# psoc6_01 register map
Vendor: Cypress Semiconductor; Series: PSoC6_01; File version: 1.0
CPU: CM4 r0p1, little endian, MPU, FPU, VTOR, 3 interrupt priority bits
Registers are 32-bit, read-write, reset 0x0 unless marked. A register's access mark holds for its fields unless they carry their own. Offsets are from the block's base; [hi:lo] are bit positions; {n}, {i} and the like mark numbered series.

## SCB0 (part 1 of 2) — Serial Communications Block (SPI/UART/I2C)
Base 0x40610000
Same registers: SCB{n} {0x40610000+0x10000*n} (n=1..8)
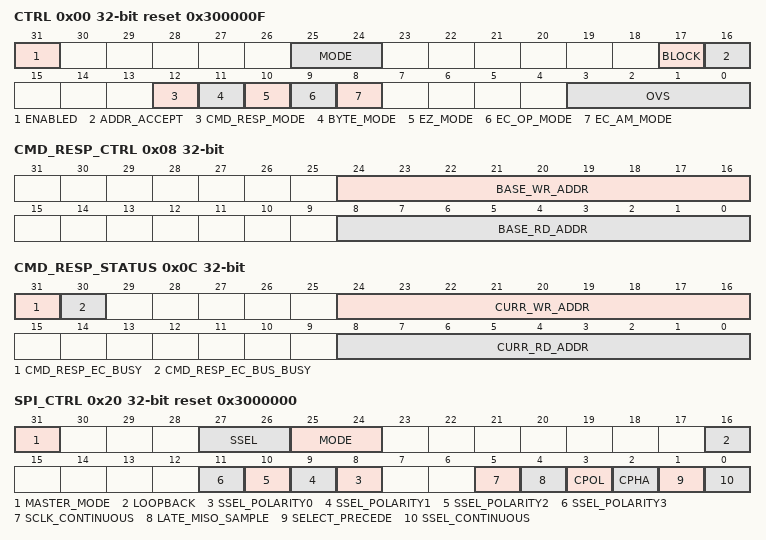
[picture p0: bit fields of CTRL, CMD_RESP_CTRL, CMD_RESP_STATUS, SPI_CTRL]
0x00 CTRL reset 0x300000F — Generic control
  [31] ENABLED — 0': Block Disabled '1': Block Enabled The proper order in which to initialize the SCB is as follows: - Program protocol specific information using SPI_CTRL, UART_CTRL (and UART_TX_CTRL and UART_RX_CTRL) or I2C_CTRL. This includes selection of a submode, master/slave functionality and transmitter/receiver functionality when applicable. - Program generic transmitter (TX_CTRL) and receiver (RX_CTRL) information. This includes enabling of the transmitter and receiver functionality. - Program transmitter FIFO (TX_FIFO_CTRL) and receiver FIFO (RX_FIFO_CTRL) information. - Program CTRL to enable SCB, select the specific operation mode and oversampling factor. When the SCB is enabled, no control information should be changed. Changes must be made AFTER disabling the SCB, e.g. to modify the operation mode (from I2C to SPI) or to go from externally to internally clocked. The change takes effect after the SCB is re-enabled. Note that disabling the SCB will cause re-initialization of the design and associated state is lost (e.g. FIFO content).
  [25:24] MODE
    0=I2C (N/A); 1=SPI (N/A); 2=UART (N/A)
  [17] BLOCK — Only used in externally clocked mode. If the externally clocked logic and the CPU access the EZ memory at the same time this bit determines whether a CPU access should block and result in bus wait states '0': Do not block, but ingore a write and return 0xffff:ffff for a read '1': Block, resulting in CPU wait states. If BLOCK is '0' and the accesses collide, CPU read operations return 0xffff:ffff and CPU write operations are ignored. Colliding accesses are registered as interrupt causes: field BLOCKED of the INTR_TX and INTR_RX registers.
  [16] ADDR_ACCEPT — Determines whether a received matching address is accepted in the RX FIFO:. '0': Matching address does not go in RX FIFO '1': Match address does go in RX FIFO In I2C mode, this field is used to allow the slave to put the received slave address or general call address in the RX FIFO. Note that a received matching address is put in the RX FIFO when this bit is '1' for both I2C read and write transfers. In multi-processor UART receiver mode, this field is used to allow the receiver to put the received address in the RX FIFO. Note: non-matching addresses are never put in the RX FIFO. In SPI mode this field must be '0'
  [12] CMD_RESP_MODE — Determines CMD_RESP mode of operation: '0': CMD_RESP mode disabled. '1': CMD_RESP mode enabled (also requires EC_AM_MODE and EC_OP_MODE to be set to '1'). In CMD_RESP mode, a meta protocol is applied to the serial interface protocol. This meta protocol adds meaning to the data frames transferred by the serial interface protocol: a data frame can represent a write memory data element or a read memory data element. The difference from EZ mode is that the address is written by the CPU, not the interface master. CMD_RESP mode can only be used for synchronous serial interface protocols (SPI and I2C) in slave mode. In SPI mode, only Motorola submode (all Motorola modes: 0, 1, 2, 3) is supported. The external master should use continuous data frames; i.e. data frames not seperated by slave deselection. In CMD_RESP mode, data frames should 8-bit in size and should be transmitted and received with the Most Significant Bit (MSB) first. In UART mode this field must be '0'.
  [11] BYTE_MODE
  [10] EZ_MODE — This field determines if EZ mode is enabled or disabled for the SCB block '0': EZ Mode Disabled '1': EZ Mode Enabled In EZ mode, a meta protocol is applied to the serial interface protocol. This meta protocol adds meaning to the data frames transferred by the serial interface protocol: a data frame can represent a memory address, a write memory data element or a read memory data element. EZ mode can only be used for synchronous serial interface protocols (SPI and I2C) in slave mode. In SPI mode, only Motorola submode (all Motorola modes: 0, 1, 2, 3) is supported. The external master should use continuous data frames; i.e. data frames not seperated by slave deselection. In EZ mode, data frames should 8-bit in size and should be transmitted and received with the Most Significant Bit (MSB) first. In UART mode this field must be '0'.
  [9] EC_OP_MODE — This field specifies the clocking for the SCB block after the address phase '0': Internally clocked mode '1': externally clocked mode In internally clocked mode, the serial interface protocols run off the clk_scb. In externally clocked mode, the serial interface protocols run off the clock as provided by the serial interface. Externally clocked operation mode is only used for synchronous serial interface protocols (SPI and I2C) in slave mode. In SPI mode, only Motorola submode (all Motorola modes: 0, 1, 2, 3) is supported. In UART mode this field must be '0'.
  [8] EC_AM_MODE — This field specifies the clocking for the address matching (I2C slave) or slave selection detection logic (SPI slave) '0': Internally clocked mode '1': Externally clocked mode In internally clocked mode the address detection(and slave selection detection) is done by clk_scb, and thus won't be done in deep sleep power mode as clk_scb isn't active. In externally clocked mode the address detection is done by the I2C/SPI interface clock. This allows for the device to be awoken on I2C salve address match and SPI slave select assertion. The clocking for the rest of the logic is determined by CTRL.EC_OP_MODE. Externally clocked mode is only used for synchronous serial interface protocols (SPI and I2C) in slave mode. In SPI mode, only Motorola submode (all Motorola modes: 0, 1, 2, 3) is supported. In UART mode this field must be '0'.
  [3:0] OVS
0x04 STATUS ro reset not defined — Generic status
  [0] EC_BUSY — Inidicates whether the externally clocked logic is potentially accessing the EZ memory (this is only possible in EZ and CMD_RESP mode). This bit can be used by SW to determine whether it is safe for the CPU to access the EZ memory (without bus wait states (a blocked CPU access) or bus errors being generated). Note that the INTR_TX.BLOCKED and INTR_RX.BLOCKED interrupt causes are used to indicate whether CPU access was actually blocked by externally clocked logic.
0x08 CMD_RESP_CTRL — Command/response control
  [24:16] BASE_WR_ADDR — I2C/SPI write base address for CMD_RESP mode. At the start of a write transfer this BASE_WR_ADDR is copied to CMD_RESP_STATUS.CURR_WR_ADDR. This field should not be modified during ongoing bus transfers.
  [8:0] BASE_RD_ADDR — I2C/SPI read base address for CMD_RESP mode. At the start of a read transfer this BASE_RD_ADDR is copied to CMD_RESP_STATUS.CURR_RD_ADDR. This field should not be modified during ongoing bus transfers.
0x0C CMD_RESP_STATUS ro reset not defined — Command/response status
  [31] CMD_RESP_EC_BUSY
  [30] CMD_RESP_EC_BUS_BUSY — Indicates whether there is an ongoing bus transfer to the SCB. '0': no ongoing bus transfer. '1': ongoing bus transfer. For SPI, the field is '1' when slave mode is selected. For I2C, the field is set to '1' at a I2C START/RESTART. In case of an address match, the field is set to '0' on a I2C STOP. In case of NO address match, the field is set to '0' after the failing address match.
  [24:16] CURR_WR_ADDR — I2C/SPI write current address for CMD_RESP mode. HW increments the field after a write access to the memory buffer. However, when the last memory buffer address is reached, the address is NOT incremented (but remains at the maximim memory buffer address). The field is used to determine how many bytes have been written (# bytes = CURR_WR_ADDR - CMD_RESP_CTRL.BASE_WR_ADDR). This field is reliable when there is no bus transfer. This field is potentially unreliable when there is a ongoing bus transfer, i.e when CMD_RESP_EC_BUSY is '0', the field is reliable.
  [8:0] CURR_RD_ADDR — I2C/SPI read current address for CMD_RESP mode. HW increments the field after a read access to the memory buffer. However, when the last memory buffer address is reached, the address is NOT incremented (but remains at the maximim memory buffer address). The field is used to determine how many bytes have been read (# bytes = CURR_RD_ADDR - CMD_RESP_CTRL.BASE_RD_ADDR). This field is reliable when there is no bus transfer. This field is potentially unreliable when there is a ongoing bus transfer, i.e. when CMD_RESP_EC_BUSY is '0', the field is reliable.
0x20 SPI_CTRL reset 0x3000000 — SPI control
  [31] MASTER_MODE
  [27:26] SSEL — Selects one of the four incoming/outgoing SPI slave select signals: - 0: Slave 0, SSEL[0]. - 1: Slave 1, SSEL[1]. - 2: Slave 2, SSEL[2]. - 3: Slave 3, SSEL[3]. The SCB should be disabled when changes are made to this field.
  [25:24] MODE
    0=SPI_MOTOROLA (SPI Motorola submode.); 1=SPI_TI (SPI Texas Instruments submode.); 2=SPI_NS (SPI National Semiconducturs submode.)
  [16] LOOPBACK — Local loopback control (does NOT affect the information on the pins). Only used in master mode. Not used in National Semiconductors submode. '0': No local loopback '1': the SPI master MISO line is connected to the SPI master MOSI line. In other words, in loopback mode the SPI master receives on MISO what it transmits on MOSI.
  [n+8] SSEL_POLARITY{n} (n=0..3)
  [5] SCLK_CONTINUOUS
  [4] LATE_MISO_SAMPLE — Changes the SCLK edge on which MISO is captured. Only used in master mode. When '0', the default applies ( for Motorola as determined by CPOL and CPHA, for Texas Instruments on the falling edge of SCLK and for National Semiconductors on the rising edge of SCLK). When '1', the alternate clock edge is used (which comes half a SPI SCLK period later). Late sampling addresses the round trip delay associated with transmitting SCLK from the master to the slave and transmitting MISO from the slave to the master.
  [3] CPOL
  [2] CPHA
  [1] SELECT_PRECEDE — Only used in SPI Texas Instruments' submode. When '1', the data frame start indication is a pulse on the Slave SELECT line that precedes the transfer of the first data frame bit. When '0', the data frame start indication is a pulse on the Slave SELECT line that coincides with the transfer of the first data frame bit.
  [0] SSEL_CONTINUOUS — Continuous SPI data transfers enabled ('1') or not ('0'). This field is used in master mode. In slave mode, both continuous and non-continuous SPI data transfers are supported independent of this field. When continuous transfers are enabled indiviual data transfers are NOT seperated by slave select deselection as long as there is data in the TX FIFO. If the TX FIFO becomes empty then the slave select will be deselected. When continuous transfers are not enabled individual data frame transfers are always seperated by slave select deselection: independent of the availability of TX FIFO data frames.
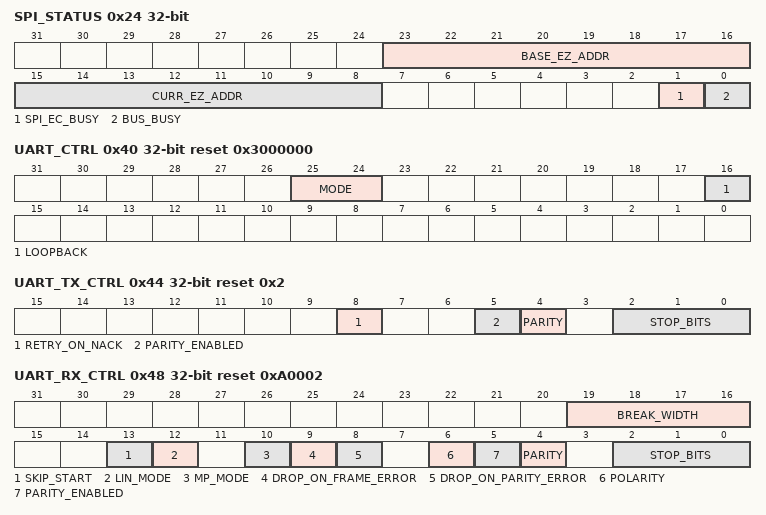
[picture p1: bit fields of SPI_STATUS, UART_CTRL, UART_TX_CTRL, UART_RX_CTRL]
0x24 SPI_STATUS ro reset not defined
  [23:16] BASE_EZ_ADDR — SPI base EZ address. Address as provided by a SPI write transfer. This field is only reliable in internally clocked mode. In externally clocked mode the field may be unreliable.
  [15:8] CURR_EZ_ADDR — SPI current EZ address. Current address pointer. This field is only reliable in internally clocked mode. In externally clocked mode the field may be unreliable (during an ongoing transfer when SPI_EC_BUSY is '1').
  [1] SPI_EC_BUSY — Inidicates whether the externally clocked logic is potentially accessing the EZ memory and/or updating BASE_ADDR or CURR_ADDR (this is only possible in EZ and CMD_RESP mode). This bit can be used by the CPU to determine whether BASE_ADDR and CURR_ADDR are reliable.
  [0] BUS_BUSY
0x40 UART_CTRL reset 0x3000000 — UART control
  [25:24] MODE
    0=UART_STD (N/A); 1=UART_SMARTCARD (N/A); 2=UART_IRDA (N/A)
  [16] LOOPBACK — Local loopback control (does NOT affect the information on the pins). 0: Loopback is not enabled 1: UART_TX is connected to UART_RX. UART_RTS is connected to UART_CTS. This allows a SCB UART transmitter to communicate with its receiver counterpart.
0x44 UART_TX_CTRL reset 0x2 — UART transmitter control
  [8] RETRY_ON_NACK
  [5] PARITY_ENABLED
  [4] PARITY
  [2:0] STOP_BITS — Stop bits. STOP_BITS + 1 is the duration of the stop period in terms of haf bit periods. Valid range is [1, 7]; i.e. a stop period should last at least one bit period.
0x48 UART_RX_CTRL reset 0xA0002 — UART receiver control
  [19:16] BREAK_WIDTH — Break width. BREAK_WIDTH + 1 is the minimum width in bit periods of a break. During a break the transmitted/received line value is '0'. This feature is useful for standard UART submode and LIN submode ('break field' detection). Once, the break is detected, the INTR_RX.BREAK_DETECT bit is set to '1'. Note for LIN the break detection precedes baud rate detection, which is used to synchronize/refine the receiver clock to the transmitter clock. As a result, break detection operates with an unsynchronized/unrefined receiver clock. Therefore, the receiver's definition of a bit period is imprecise and the setting of this field should take this imprecision into account. The LIN standard also accounts for this imprecision: a LIN start bit followed by 8 data bits allows for up to 9 consecutive '0' bit periods during regular transmission, whereas the LIN break detection should be at least 13 consecutive '0' bit periods. This provides for a margin of 4 bit periods. Therefore, the default value of this field is set to 10, representing a minimal break field with of 10+1 = 11 bit periods; a value in between the 9 consecutive bit periods of a regular transmission and the 13 consecutive bit periods of a break field. This provides for slight imprecisions of the receiver clock wrt. the transmitter clock. There should not be a need to program this field to any value other than its default value.
  [13] SKIP_START — Only applicable in standard UART submode. When '1', the receiver skips start bit detection for the first received data frame. Instead, it synchronizes on the first received data frame bit, which should be a '1'. This functionality is intended for wake up from DeepSleep when receiving a data frame. The transition from idle ('1') to START ('0') on the RX line is used to wake up the CPU. The transition detection (and the associated wake up functionality) is performed by the GPIO. The woken up CPU will enable the SCB's UART receiver functionality. Once enabled, it is assumed that the START bit is ongoing (the CPU wakeup and SCB enable time should be less than the START bit period). The SCB will then synchronize to a '0' to '1' transition, which indicates the first data frame bit is received (first data frame bit should be '1'). After synchronization to the first data frame bit, the SCB will resume normal UART functionality: subsequent data frames will be synchronized on the receipt of a START bit.
  [12] LIN_MODE — Only applicable in standard UART submode. When '1', the receiver performs break detection and baud rate detection on the incoming data. First, break detection counts the amount of bit periods that have a line value of '0'. BREAK_WIDTH specifies the minum required amount of bit periods. Successful break detection sets the INTR_RX.BREAK_DETECT interrupt cause to '1'. Second, baud rate detection counts the amount of peripheral clock periods that are use to receive the synchronization byte (0x55; least significant bit first). The count is available through UART_RX_STATUS.BR_COUNTER. Successful baud rate detection sets the INTR_RX.BAUD_DETECT interrupt cause to '1' (BR_COUNTER is reliable). This functionality is used to synchronize/refine the receiver clock to the transmitter clock. The receiver software can use the BR_COUNTER value to set the right clk_scb to guarantee successful receipt of the first LIN data frame (Protected Identifier Field) after the synchronization byte.
  [10] MP_MODE — Multi-processor mode. When '1', multi-processor mode is enabled. In this mode, RX_CTRL.DATA_WIDTH must be 9 bits. In multi-processor mode, the 9th received bit of a data frame seperates addresses (bit is '1') from data (bit is '0'). A received address is matched with RX_MATCH.DATA and RX_MATCH.MASK. In the case of a match, subsequent received data is sent to the RX FIFO. In the case of NO match, subsequent received data is dropped.
  [9] DROP_ON_FRAME_ERROR — Behaviour when an error is detected in a start or stop period. When '0', received data is sent to the RX FIFO. When '1', received data is dropped and lost.
  [8] DROP_ON_PARITY_ERROR
  [6] POLARITY — Inverts incoming RX line signal 'uart_rx_in'. Inversion is after local loopback. This functionality only works for IrDA receiver functionality.
  [5] PARITY_ENABLED
  [4] PARITY
  [2:0] STOP_BITS — Stop bits. STOP_BITS + 1 is the duration of the stop period in terms of haf bit periods. Valid range is [1, 7]; i.e. a stop period should last at least one bit period. If STOP_BITS is '1', stop bits error detection is NOT performed. If STOP_BITS is in [2, 7], stop bits error detection is performed and the associated interrupt cause INTR_RX.FRAME_ERROR is set to '1' if an error is detected. In other words, the receiver supports data frames with a 1 bit period stop bit sequence, but requires at least 1.5 bit period stop bit sequences to detect errors. Note that in case of a stop bits error, the successive data frames may get lost as the receiver needs to resynchronize its start bit detection. The amount of lost data frames depends on both the amount of stop bits, the idle time between data frames and the data frame value.
0x4C UART_RX_STATUS ro reset not defined — UART receiver status
  [11:0] BR_COUNTER — For LIN: Amount of clk_scb periods that constitute the transmission of a 0x55 data frame (sent least signficant bit first) as determined by the receiver. BR_COUNTER / 8 is the amount of clk_scb periods that constitute a bit period. This field has valid data when INTR_RX.BAUD_DETECT is set to '1'.
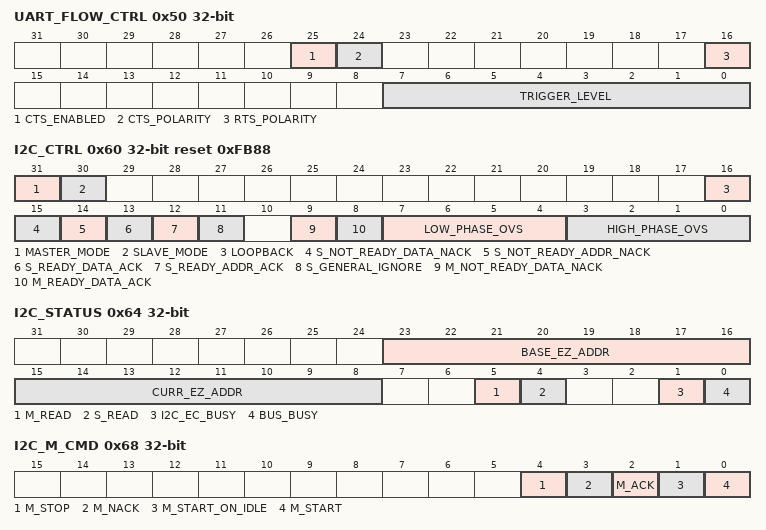
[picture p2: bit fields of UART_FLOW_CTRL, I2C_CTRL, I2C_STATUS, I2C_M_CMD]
0x50 UART_FLOW_CTRL — UART flow control
  [25] CTS_ENABLED — Enable use of CTS input signal by the UART transmitter: '0': Disabled. The UART transmitter ignores the CTS input signal and transmits when a data frame is available for transmission in the TX FIFO or the TX shift register. '1': Enabled. The UART transmitter uses CTS input signal to qualify the transmission of data. It transmits when CTS input signal is active and a data frame is available for transmission in the TX FIFO or the TX shift register. If UART_CTRL.LOOPBACK is '1', the CTS input signal is driven by the RTS output signal locally in SCB (both signals are subjected to signal polarity changes are indicated by RTS_POLARITY and CTS_POLARITY).
  [24] CTS_POLARITY — Polarity of the CTS input signal '0': CTS is active low ; '1': CTS is active high;
  [16] RTS_POLARITY — Polarity of the RTS output signal: '0': RTS is active low; '1': RTS is active high; During SCB reset (Hibernate system power mode), RTS output signal is '1'. This represents an inactive state assuming an active low polarity.
  [7:0] TRIGGER_LEVEL — Trigger level. When the receiver FIFO has less entries than the amount of this field, a Ready To Send (RTS) output signal is activated. By setting this field to '0', flow control is disabled
0x60 I2C_CTRL reset 0xFB88 — I2C control
  [31] MASTER_MODE — Master mode enabled ('1') or not ('0'). Note that both master and slave modes can be enabled at the same time. This allows the SCB to address itself.
  [30] SLAVE_MODE
  [16] LOOPBACK — Local loopback control (does NOT affect the information on the pins). Only applicable in master/slave mode. When '0', no loopback When '1', loopback is enabled internally in the peripheral, and as a result unaffected by other I2C devices. This allows a SCB I2C peripheral to address itself.
  [15] S_NOT_READY_DATA_NACK — Only used for FIFO mode, NOT EZ or CMD_RESP mode. Functionality is as follows: - 1: a received data element byte the slave is immediately NACK'd when the receiver FIFO is full. - 0: clock stretching is performed (till the receiver FIFO is no longer full).
  [14] S_NOT_READY_ADDR_NACK — Only used for FIFO mode, NOT EZ or CMD_RESP mode. Functionality is as follows: - 1: In Active/Sleep mode a received (matching) slave address is immediately NACK'd when the RX FIFO is full In DeepSleep power mode when EC_AM = '1' and EC_OP = '0' clk_scb is not avaliable, so the incoming address will be NACK'd until the clock is avaliable. Once clk_scb is avaliable the address ACK will follow S_READY_ADDR_ACK - 0: in Active/Sleep mode clock stretching is performed when the RX FIFO is full, the strech is released when the RX FIFO is no longer full. In DeepSleep power mode when EC_AM = '1' and EC_OP = '0' clk_scb is not avaliable, so the clocked will be streched on an incoming address until clk_scb is avaliable. After clk_scb is avalaible the address ACK will follow S_READY_ADDR_ACK
  [13] S_READY_DATA_ACK — When '1', a received data element by the slave is immediately ACK'd when the RX FIFO is not full. In EZ and CMD_RESP mode, this field should be set to '1'. When '0' the data must be ACK/NACK'd by the CPU using I2C_S_CMD.S_ACK or I2C_S_CMD.S_NACK
  [12] S_READY_ADDR_ACK — When '1', a received (matching) slave address is immediately ACK'd when the RX FIFO is not full. In EZ and CMD_RESP mode, this field should be set to '1'. When '0' the address must be ACK/NACK'd by the CPU using I2C_S_CMD.S_ACK or I2C_S_CMD.S_NACK
  [11] S_GENERAL_IGNORE — When '1', a received general call slave address is immediately NACK'd (no ACK or clock stretching) and treated as a non matching slave address. This is useful for slaves that do not need any data supplied within the general call structure. When '0' the general call address is accepted and follows S_READY_ADDR_ACK and S_NOT_READY_ADDR_NACK
  [9] M_NOT_READY_DATA_NACK — When '1', a received data element by the master is immediately NACK'd when the RX FIFO is full. When '0', clock stretching is used instead (till the RX FIFO is no longer full).
  [8] M_READY_DATA_ACK — When '1', a received data element by the master is immediately ACK'd when the RX FIFO is not full. When '0' the CPU is responsible for ACK/NACKing the received data frame using I2C_M_CMD.M_ACK or I2C_M_CMD.M_NACK
  [7:4] LOW_PHASE_OVS — Serial I2C interface low phase oversampling factor. (LOW_PHASE_OVS + 1) * clk_scb constitutes the low phase of a bit period. The valid range is [7, 15] with input signal median filtering and [6, 15] without input signal median filtering. The field is only used in master mode. In slave mode, the field is NOT used. See architecture TRM for information on slave data rate requirments.
  [3:0] HIGH_PHASE_OVS — Serial I2C interface high phase oversampling factor. (HIGH_PHASE_OVS + 1) * clk_scb constitutes the high phase of a bit period. The valid range is [5, 15] with input signal median filtering and [4, 15] without input signal median filtering. The field is only used in master mode. In slave mode, the field is NOT used. See architecture TRM for information on slave data rate requirments.
0x64 I2C_STATUS ro (reset mask 0x31)
  [23:16] BASE_EZ_ADDR — I2C slave base EZ address. Address as provided by an I2C write transfer. This field is only reliable in internally clocked mode. In externally clocked mode the field may be unreliable.
  [15:8] CURR_EZ_ADDR — I2C slave current EZ address. Current address pointer. This field is only reliable in internally clocked mode. In externally clocked mode the field may be unreliable (during an ongoing transfer when I2C_EC_BUSY is '1').
  [5] M_READ
  [4] S_READ
  [1] I2C_EC_BUSY — Inidicates whether the externally clocked logic is potentially accessing the EZ memory and/or updating BASE_ADDR or CURR_ADDR (this is only possible in EZ and CMD_RESP mode). This bit can be used by the CPU to determine whether BASE_ADDR and CURR_ADDR are reliable.
  [0] BUS_BUSY — I2C bus is busy. The bus is considered busy ('1'), from the time a START is detected or from the time the SCL line is '0'. The bus is considered idle ('0'), from the time a STOP is detected. If the SCB is disabled, BUS_BUSY is '0'. After enabling the SCB, it takes time for the BUS_BUSY to detect a busy bus. This time is the maximum high time of the SCL line. For a 100 kHz interface frequency, this maximum high time may last roughly 5 us (half a bit period). For single master systems, BUS_BUSY does not have to be used to detect an idle bus before a master starts a transfer using I2C_M_CMD.M_START (no bus collisions). For multi-master systems, BUS_BUSY can be used to detect an idle bus before a master starts a transfer using I2C_M_CMD.M_START_ON_IDLE (to prevent bus collisions).
0x68 I2C_M_CMD — I2C master command
  [4] M_STOP
  [3] M_NACK
  [2] M_ACK
  [1] M_START_ON_IDLE — When '1', transmit a START as soon as the bus is idle (I2C_STATUS.BUS_BUSY is '0', note that BUSY has a default value of '0'). For bus idle detection the hardware relies on STOP detection. As a result, bus idle detection is only functional after at least one I2C bus transfer has been detected on the bus (default/reset value of BUSY is '0') . A START is only transmitted when the master state machine is in the default state. When this action is performed, the hardware sets this field to '0'.
  [0] M_START — When '1', transmit a START or REPEATED START. Whether a START or REPEATED START is transmitted depends on the state of the master state machine. A START is only transmitted when the master state machine is in the default state. A REPEATED START is transmitted when the master state machine is not in the default state, but is working on an ongoing transaction. The REPEATED START can only be transmitted after a NACK or ACK has been received for a transmitted data element or after a NACK has been transmitted for a received data element. When this action is performed, the hardware sets this field to '0'.
